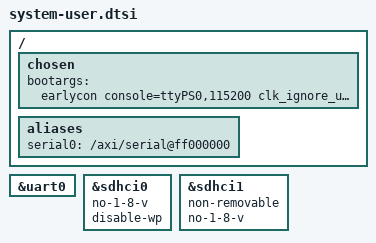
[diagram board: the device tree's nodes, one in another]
/include/ "system-conf.dtsi"
/ {
	chosen {
		bootargs = "earlycon console=ttyPS0,115200 clk_ignore_unused root=/dev/mmcblk0p2 rw rootwait";
	};

	aliases {
		serial0 = "/axi/serial@ff000000";
	};
};

&uart0 {
	status = "okay";
};

&sdhci0 {
	status = "okay";
	no-1-8-v;
	disable-wp;
};

&sdhci1 {
	status = "okay";
	non-removable;
	no-1-8-v;
};
